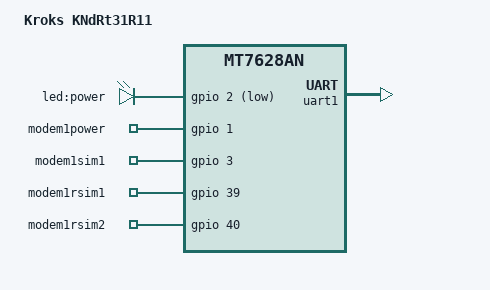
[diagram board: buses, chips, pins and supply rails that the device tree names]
#include "mt7628an_kroks_1eth.dtsi"

/ {
	compatible = "kroks,kndrt31r11", "mediatek,mt7628an-soc";
	model = "Kroks KNdRt31R11";

	aliases {
		led-boot = &led_power;
		led-failsafe = &led_power;
		led-running = &led_power;
		led-upgrade = &led_power;
		serial1 = &uart1;
	};

	leds {
		compatible = "gpio-leds";

		led_power: power {
			label = "led:power";
			gpios = <&gpio 2 GPIO_ACTIVE_LOW>;
		};
	};

	gpio_export {
		compatible = "gpio-export";
		#size-cells = <0>;

		modem1power {
			gpio-export,name = "modem1power";
			gpio-export,output = <1>;
			gpios = <&gpio 1 GPIO_ACTIVE_HIGH>;
		};

		modem1sim1 {
			gpio-export,name = "modem1sim1";
			gpio-export,output = <0>;
			gpios = <&gpio 3 GPIO_ACTIVE_HIGH>;
		};

		modem1rsim1 {
			gpio-export,name = "modem1rsim1";
			gpio-export,output = <1>;
			gpios = <&gpio 39 GPIO_ACTIVE_HIGH>;
		};

		modem1rsim2 {
			gpio-export,name = "modem1rsim2";
			gpio-export,output = <0>;
			gpios = <&gpio 40 GPIO_ACTIVE_HIGH>;
		};
	};
};

&uart1 {
	status = "okay";
};

&state_default {
	gpio {
		groups = "i2s", "p4led_an", "p3led_an";
		function = "gpio";
	};
};

&wmac {
	status = "disabled";
};
